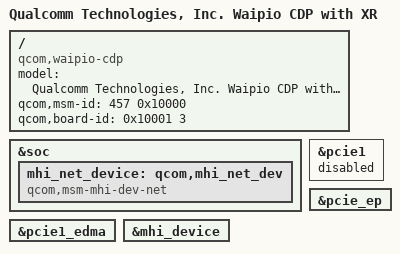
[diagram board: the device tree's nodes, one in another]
/dts-v1/;
/plugin/;

#include "waipio-cdp.dtsi"

/ {
	model = "Qualcomm Technologies, Inc. Waipio CDP with XR";
	compatible = "qcom,waipio-cdp", "qcom,waipio", "qcom,cdp";
	qcom,msm-id = <457 0x10000>;
	qcom,board-id = <0x10001 3>;
};

&soc {
	mhi_net_device: qcom,mhi_net_dev {
		compatible = "qcom,msm-mhi-dev-net";
	};
};

&pcie1 {
	status = "disabled";
};

&pcie1_edma {
	status = "ok";

};

&pcie_ep {
	status = "ok";
};

&mhi_device {
	status = "ok";
};
